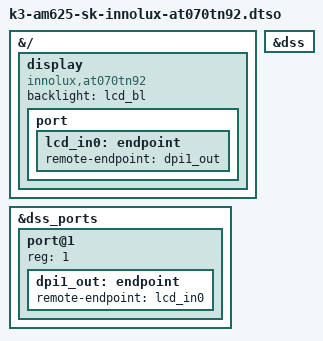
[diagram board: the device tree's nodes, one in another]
// SPDX-License-Identifier: GPL-2.0-or-later OR MIT
/*
 * Innolux AT070TN92 panel overlay for AM625 SK / CX-AM62x.
 *
 * ===== CRZ CHANGED: rewritten as a DPI panel on VP2 =====
 * The AT070TN92 is a 7" RGB-parallel (DPI) panel wired to VOUT0 (see the
 * CX-AM62x "LCD I/F (RGB)" schematic sheet and the old port's U-Boot
 * dtbo_idx==1 DPI pixel-clock workaround); the previous version of this
 * overlay wrongly routed it through the OLDI (LVDS) transmitters, which the
 * 6.12 tidss OLDI bridge rejects for its RGB888_1X24 bus format.
 * dss_ports port@1 is VP2 = DPI out (see k3-am62-main.dtsi).
 * Timings come from the panel-simple "innolux,at070tn92" descriptor; a
 * panel-timing node here would only trigger "Reject override mode" warnings.
 */

/dts-v1/;
/plugin/;

&{/} {
	display {
		compatible = "innolux,at070tn92", "panel-simple";
		backlight = <&lcd_bl>;

		port {
			lcd_in0: endpoint {
				remote-endpoint = <&dpi1_out>;
			};
		};
	};
};

&dss {
	status = "okay";
};

&dss_ports {
	#address-cells = <1>;
	#size-cells = <0>;

	port@1 {
		reg = <1>;
		dpi1_out: endpoint {
			remote-endpoint = <&lcd_in0>;
		};
	};
};
